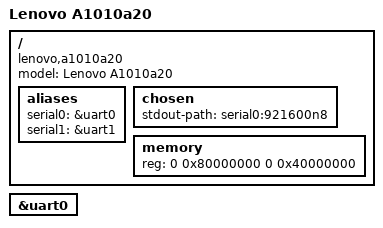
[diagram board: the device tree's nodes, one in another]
// SPDX-License-Identifier: GPL-2.0
/*
 * Copyright (c) 2023 Evgeniy Filimonov <fil.eugene@gmail.com>
 */

/dts-v1/;
#include "mt6580.dtsi"

/ {
	model = "Lenovo A1010a20";
	compatible = "lenovo,a1010a20", "mediatek,mt6580";

	aliases {
		serial0 = &uart0;
		serial1 = &uart1;
	};

	chosen {
		stdout-path = "serial0:921600n8";
	};

	memory {
		device_type = "memory";
		reg = <0 0x80000000 0 0x40000000>;
	};
};

&uart0 {
	status = "okay";
};
